VERSION ""

NS_ :

BS_:

BU_: Precharge_Controller

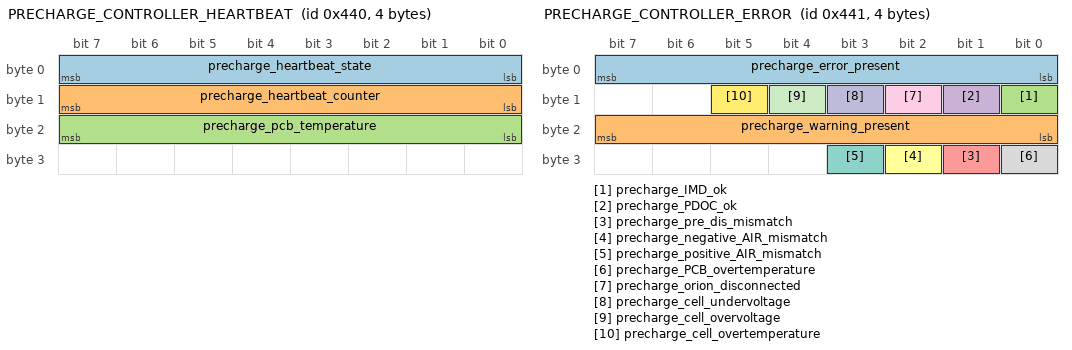
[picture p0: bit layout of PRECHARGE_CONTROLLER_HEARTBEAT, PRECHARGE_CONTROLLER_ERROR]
BO_ 1088 PRECHARGE_CONTROLLER_HEARTBEAT: 4 Precharge_Controller
 SG_ precharge_heartbeat_state : 0|8@1+ (1,0) [0|0] "" Vector__XXX
 SG_ precharge_heartbeat_counter : 8|8@1+ (1,0) [0|0] "" Vector__XXX
 SG_ precharge_pcb_temperature : 16|8@1+ (1,0) [0|0] "" Vector__XXX

BO_ 1089 PRECHARGE_CONTROLLER_ERROR: 4 Precharge_Controller
 SG_ precharge_error_present : 0|8@1+ (1,0) [0|0] "" Vector__XXX
 SG_ precharge_warning_present : 16|8@1+ (1,0) [0|0] "" Vector__XXX
 SG_ precharge_IMD_ok : 8|1@1+ (1,0) [0|0] "" Vector__XXX
 SG_ precharge_PDOC_ok : 9|1@1+ (1,0) [0|0] "" Vector__XXX
 SG_ precharge_pre_dis_mismatch : 25|1@1+ (1,0) [0|0] "" Vector__XXX
 SG_ precharge_negative_AIR_mismatch : 26|1@1+ (1,0) [0|0] "" Vector__XXX
 SG_ precharge_positive_AIR_mismatch : 27|1@1+ (1,0) [0|0] "" Vector__XXX
 SG_ precharge_PCB_overtemperature : 24|1@1+ (1,0) [0|0] "" Vector__XXX
 SG_ precharge_orion_disconnected : 10|1@1+ (1,0) [0|0] "" Vector__XXX
 SG_ precharge_cell_undervoltage : 11|1@1+ (1,0) [0|0] "" Vector__XXX
 SG_ precharge_cell_overvoltage : 12|1@1+ (1,0) [0|0] "" Vector__XXX
 SG_ precharge_cell_overtemperature : 13|1@1+ (1,0) [0|0] "" Vector__XXX

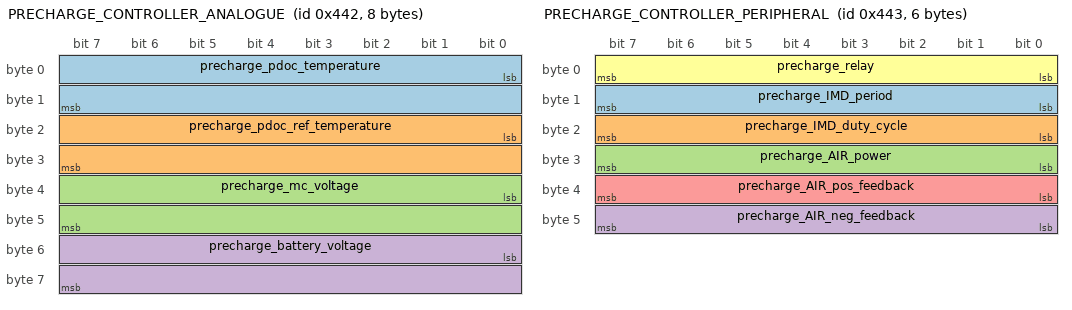
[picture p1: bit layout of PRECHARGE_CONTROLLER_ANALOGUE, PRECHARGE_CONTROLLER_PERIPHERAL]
BO_ 1090 PRECHARGE_CONTROLLER_ANALOGUE: 8 Precharge_Controller
 SG_ precharge_pdoc_temperature : 0|16@1+ (1,0) [0|0] "" Vector__XXX
 SG_ precharge_pdoc_ref_temperature : 16|16@1+ (1,0) [0|0] "" Vector__XXX
 SG_ precharge_mc_voltage : 32|16@1+ (1,0) [0|0] "" Vector__XXX
 SG_ precharge_battery_voltage : 48|16@1+ (1,0) [0|0] "" Vector__XXX

BO_ 1091 PRECHARGE_CONTROLLER_PERIPHERAL: 6 Precharge_Controller
 SG_ precharge_IMD_period : 8|8@1+ (1,0) [0|0] "" Vector__XXX
 SG_ precharge_IMD_duty_cycle : 16|8@1+ (1,0) [0|0] "" Vector__XXX
 SG_ precharge_AIR_power : 24|8@1+ (1,0) [0|0] "" Vector__XXX
 SG_ precharge_AIR_neg_feedback : 40|8@1+ (1,0) [0|0] "" Vector__XXX
 SG_ precharge_AIR_pos_feedback : 32|8@1+ (1,0) [0|0] "" Vector__XXX
 SG_ precharge_relay : 0|8@1+ (1,0) [0|0] "" Vector__XXX
